# CTRL_MMR0 register map
Vendor: Texas Instruments
Peripheral module from a debugger description file (folder J7ES).
Registers are 32-bit, access per field, reset 0x0 unless marked. A register's access mark holds for its fields unless they carry their own. Offsets are as the file gives them; lines under a group give offsets from that group; [hi:lo] are bit positions; {n}, {i} and the like mark numbered series; 'fields as' and 'values as' point back to an identical list; <NAME> marks a mode.

## CTRL_MMR0 (part 1 of 2)
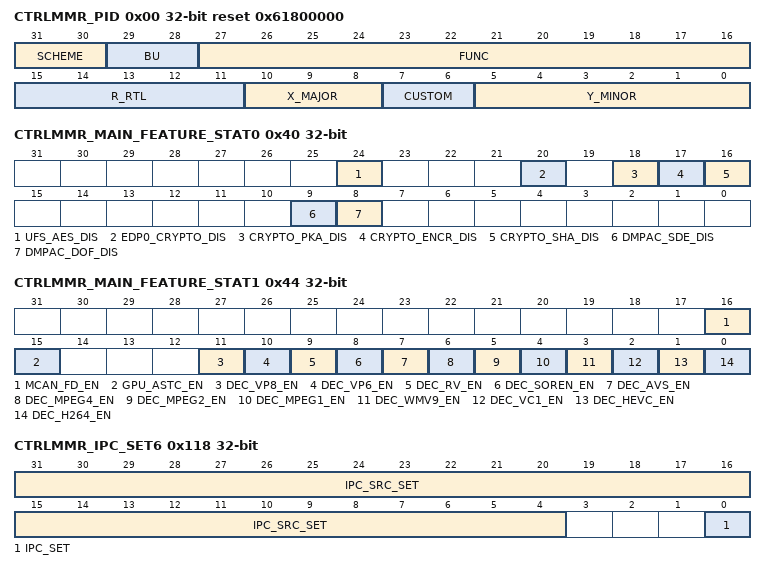
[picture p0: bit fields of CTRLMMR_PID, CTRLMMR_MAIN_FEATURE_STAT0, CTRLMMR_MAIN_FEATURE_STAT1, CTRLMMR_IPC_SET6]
0x00 CTRLMMR_PID ro reset 0x61800000 — Peripheral release details.
  [31:30] SCHEME
  [29:28] BU — Business unit
  [27:16] FUNC — Module functional identifier
  [15:11] R_RTL — RTL revision
  [10:8] X_MAJOR — Major revision
  [7:6] CUSTOM — Custom revision
  [5:0] Y_MINOR — Minor revision
0x08 CTRLMMR_MMR_CFG1 ro reset 0x8000009F — Indicates the MMR configuration.
  [7:0] PARTITIONS — Indicates present partitions
0x30 CTRLMMR_MAIN_DEVSTAT (reset mask 0xFFFFFF00) — Indicates SoC bootstrap selection. The default value of this register is determined by the SoC bootstrap pins when the por_boot_cfg_srst_n input is de-asserted. Note that this register will not be valid when returning from Deepsleep powerdown modes as the bootstrap pins are not relatched in this scenario.
  [7:0] BOOTMODE rw — Specifies the device Primary and Backup boot media.
0x34 CTRLMMR_MAIN_BOOTCFG ro (reset mask 0xFFFFFF00) — Indicates SoC bootstrap selection latched at power-on reset by PORz. The default value of this register is determined by the SoC bootstrap pins when the MMR por_boot_cfg_srst_n input is de-asserted and will remain until the SOC bootstrap pins are re-latched on a subsequent MMR por_boot_cfg_srst_n rising edge. Note that this register will not be valid when returning from Deepsleep powerdown modes as the bootstrap pins are not relatched in this scenario.
  [7:0] BOOTMODE — Specifies the device Primary and Backup boot media.
0x40 CTRLMMR_MAIN_FEATURE_STAT0 ro (reset mask 0xFEE8FCFC) — Indicates enable status of MAIN domain IP features.
  [24] UFS_AES_DIS — AES disabled on UFS
  [20] EDP0_CRYPTO_DIS — HDCP Cryptography disabled on eDP0
  [18] CRYPTO_PKA_DIS — SA2_UL Crypto Module PKA disabled
  [17] CRYPTO_ENCR_DIS — SA2_UL Crypto Module AES/3DES/DBRG disabled
  [16] CRYPTO_SHA_DIS — SA2_UL Crypto Module SHA/MD5 disabled
  [9] DMPAC_SDE_DIS — DMPAC Stereo Disparity Engine disabled
  [8] DMPAC_DOF_DIS — DMPAC Dense Optical Flow disabled
0x44 CTRLMMR_MAIN_FEATURE_STAT1 ro (reset mask 0xFFFE7000) — Indicates enable status of MAIN domain IP features.
  [16] MCAN_FD_EN — FD mode is supported on MAIN MCAN interfaces when set
  [15] GPU_ASTC_EN — GPU Adaptive Scalable Texture Compression is supported when set
  [11] DEC_VP8_EN — VP8 Video decode is enabled when set
  [10] DEC_VP6_EN — VP6 Video decode is enabled when set
  [9] DEC_RV_EN — RealVideo Video decode is enabled when set
  [8] DEC_SOREN_EN — Sorenson Video decode is enabled when set
  [7] DEC_AVS_EN — AVS Video decode is enabled when set
  [6] DEC_MPEG4_EN — MPEG4 Video decode is enabled when set
  [5] DEC_MPEG2_EN — MPEG2 Video decode is enabled when set
  [4] DEC_MPEG1_EN — MPEG1 Video decode is enabled when set
  [3] DEC_WMV9_EN — WMV9 Video decode is enabled when set
  [2] DEC_VC1_EN — VC-1 (SMPTE 421M) Video decode is enabled when set
  [1] DEC_HEVC_EN — HEVC (H.265) Video decode is enabled when set
  [0] DEC_H264_EN — H.264 Video decode is enabled when set
0x118 CTRLMMR_IPC_SET6 access not given — Generate interprocessor communication interrupt to C66 core0.
  [31:4] IPC_SRC_SET — Read returns current value (access W1TS)
  [0] IPC_SET — Read returns 0 (access W1TS)
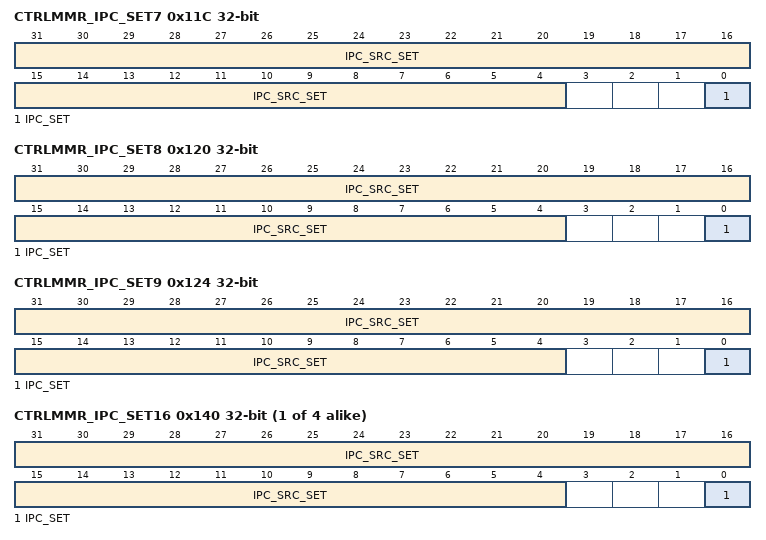
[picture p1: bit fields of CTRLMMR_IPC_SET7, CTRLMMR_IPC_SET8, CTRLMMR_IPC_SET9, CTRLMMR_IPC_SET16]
0x11C CTRLMMR_IPC_SET7 access not given — Generate interprocessor communication interrupt to C66 core1.
  fields as CTRLMMR_IPC_SET6
0x120 CTRLMMR_IPC_SET8 access not given — Generate interprocessor communication interrupt to ARM MPU core0.
  fields as CTRLMMR_IPC_SET6
0x124 CTRLMMR_IPC_SET9 access not given — Generate interprocessor communication interrupt to ARM MPU core1.
  fields as CTRLMMR_IPC_SET6
{0x100+4i} CTRLMMR_IPC_SET{i} access not given (i=16..19) — Generate interprocessor communication interrupt to MAIN R5 core{i-16}.
  fields as CTRLMMR_IPC_SET6
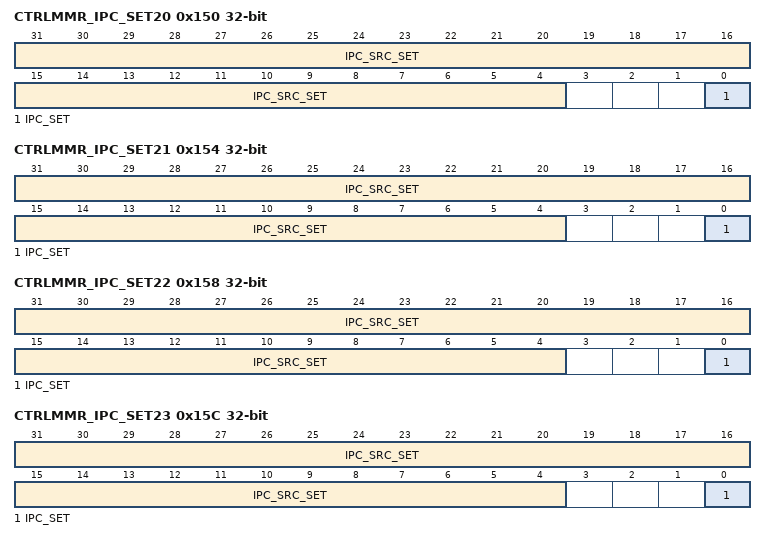
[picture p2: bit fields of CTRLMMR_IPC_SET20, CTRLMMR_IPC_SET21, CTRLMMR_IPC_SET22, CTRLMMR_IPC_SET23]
0x150 CTRLMMR_IPC_SET20 access not given — Generate interprocessor communication interrupt to ICSSG0 PRU0.
  fields as CTRLMMR_IPC_SET6
0x154 CTRLMMR_IPC_SET21 access not given — Generate interprocessor communication interrupt to ICSSG0 PRU1.
  fields as CTRLMMR_IPC_SET6
0x158 CTRLMMR_IPC_SET22 access not given — Generate interprocessor communication interrupt to ICSSG1 PRU0.
  fields as CTRLMMR_IPC_SET6
0x15C CTRLMMR_IPC_SET23 access not given — Generate interprocessor communication interrupt to ICSSG1 PRU1.
  fields as CTRLMMR_IPC_SET6
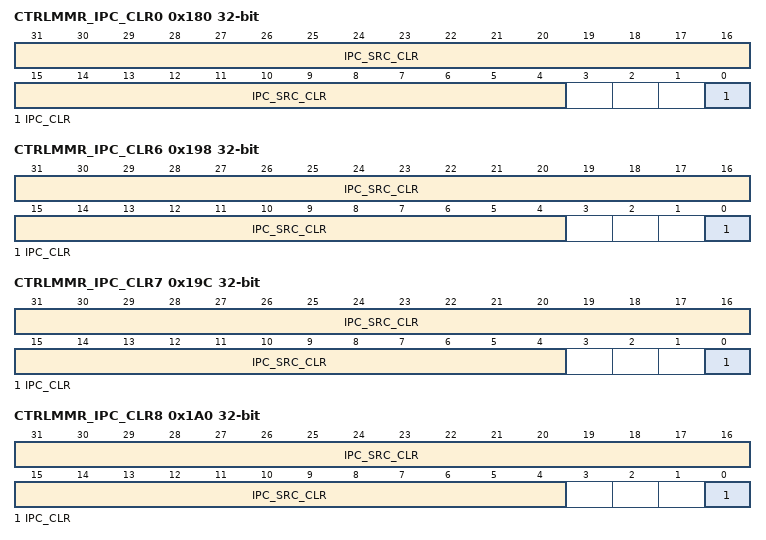
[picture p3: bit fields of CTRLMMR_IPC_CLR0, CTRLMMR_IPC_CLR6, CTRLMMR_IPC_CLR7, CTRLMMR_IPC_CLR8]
0x180 CTRLMMR_IPC_CLR0 access not given — Acknowledge interprocessor communication interrupt to C71x core0.
  [31:4] IPC_SRC_CLR — Read returns current value (access W1TC)
  [0] IPC_CLR — Read returns current value (access W1TC)
0x198 CTRLMMR_IPC_CLR6 access not given — Acknowledge interprocessor communication interrupt to C66 core0.
  fields as CTRLMMR_IPC_CLR0
0x19C CTRLMMR_IPC_CLR7 access not given — Acknowledge interprocessor communication interrupt to C66 core1.
  fields as CTRLMMR_IPC_CLR0
0x1A0 CTRLMMR_IPC_CLR8 access not given — Acknowledge interprocessor communication interrupt to ARM MPU core0.
  fields as CTRLMMR_IPC_CLR0
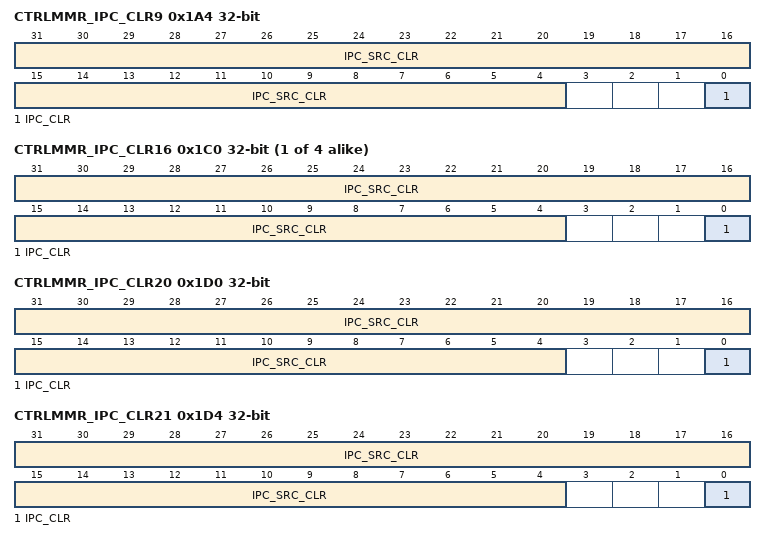
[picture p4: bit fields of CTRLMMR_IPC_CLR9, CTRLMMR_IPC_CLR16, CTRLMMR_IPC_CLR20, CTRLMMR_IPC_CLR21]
0x1A4 CTRLMMR_IPC_CLR9 access not given — Acknowledge interprocessor communication interrupt to ARM MPU core1.
  fields as CTRLMMR_IPC_CLR0
{0x180+4i} CTRLMMR_IPC_CLR{i} access not given (i=16..19) — Acknowledge interprocessor communication interrupt to MAIN R5 core{i-16}.
  fields as CTRLMMR_IPC_CLR0
0x1D0 CTRLMMR_IPC_CLR20 access not given — Acknowledge interprocessor communication interrupt to ICSSG0 PRU0.
  fields as CTRLMMR_IPC_CLR0
0x1D4 CTRLMMR_IPC_CLR21 access not given — Acknowledge interprocessor communication interrupt to ICSSG0 PRU1.
  fields as CTRLMMR_IPC_CLR0
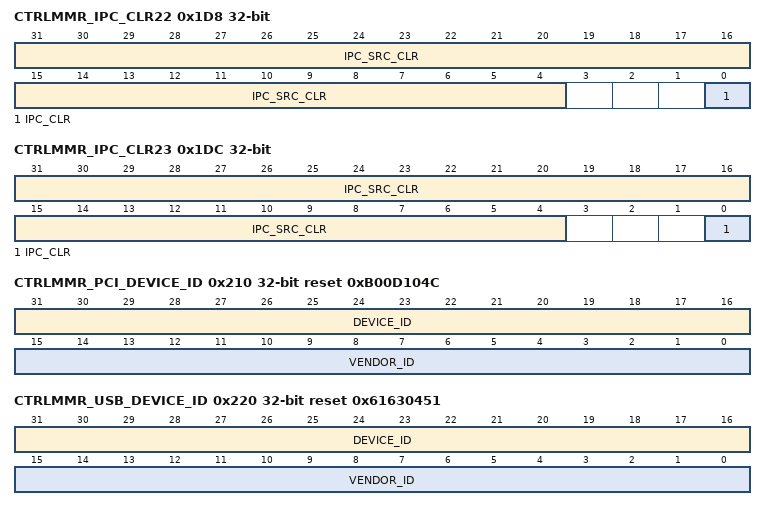
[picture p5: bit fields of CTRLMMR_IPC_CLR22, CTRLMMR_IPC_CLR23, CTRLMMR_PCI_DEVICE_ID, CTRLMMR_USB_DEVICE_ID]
0x1D8 CTRLMMR_IPC_CLR22 access not given — Acknowledge interprocessor communication interrupt to ICSSG1 PRU0.
  fields as CTRLMMR_IPC_CLR0
0x1DC CTRLMMR_IPC_CLR23 access not given — Acknowledge interprocessor communication interrupt to ICSSG1 PRU1.
  fields as CTRLMMR_IPC_CLR0
0x210 CTRLMMR_PCI_DEVICE_ID ro reset 0xB00D104C — PCIe device ID and vendor ID register.
  [31:16] DEVICE_ID — Product ID
  [15:0] VENDOR_ID — TI Vendor ID
0x220 CTRLMMR_USB_DEVICE_ID ro reset 0x61630451 — USB device and vendor ID register.
  [31:16] DEVICE_ID — Product ID
  [15:0] VENDOR_ID — TI Vendor ID
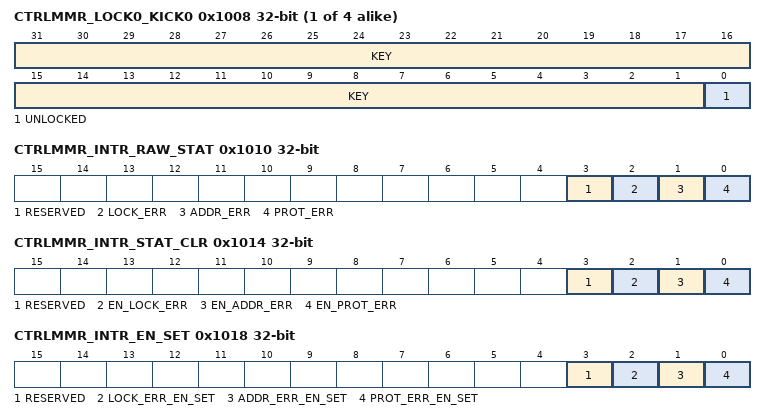
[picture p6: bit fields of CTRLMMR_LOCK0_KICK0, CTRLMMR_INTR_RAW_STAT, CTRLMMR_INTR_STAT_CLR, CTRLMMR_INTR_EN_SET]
{0x1008+0x4000*i} CTRLMMR_LOCK{i}_KICK0 (i=0..3) — Lower 32-bits of Partition{i} write lock key. This register must be written with the designated key value followed by a write to with its key value before write-protected Partition {i} registers can be written.
  [31:1] KEY rw — Write the kick0 unlock value followed by the kick1 unlock value to unlock the write-protected Partition{i} registers
  [0] UNLOCKED ro — Unlock status. When set indicates that the proper unlock sequence has been performed and the partition is unlocked for writing.
{0x100C+0x4000*i} CTRLMMR_LOCK{i}_KICK1 rw (i=0..3) — Upper 32-bits of Partition {i} write lock key. This register must be written with the designated key value after a write to with its key value before write-protected Partition {i} registers can be written.
  [31:0] KEY — Write the kick1 unlock value after the kick0 unlock value to unlock the write-protected Partition{i} registers
0x1010 CTRLMMR_INTR_RAW_STAT access not given — Shows the interrupt status (before enabling) and allows setting of the interrupt status (for test).
  [3] RESERVED — (access W1TS)
  [2] LOCK_ERR — Lock violation occurred (attempt to write a write-locked register with partition locked) (access W1TS)
  [1] ADDR_ERR — Address violation occurred (attempt to read or write an invalid register address) (access W1TS)
  [0] PROT_ERR — Protection violation occurred (attempt to read or write a register with insufficient security or privilege access rights) (access W1TS)
0x1014 CTRLMMR_INTR_STAT_CLR access not given — Shows the enabled interrupt status and allows the interrupt to be cleared.
  [3] RESERVED — (access W1TC)
  [2] EN_LOCK_ERR — Enabled lock interrupt event status (access W1TC)
  [1] EN_ADDR_ERR — Enabled address interrupt event status (access W1TC)
  [0] EN_PROT_ERR — Enabled protection interrupt event status (access W1TC)
0x1018 CTRLMMR_INTR_EN_SET access not given — Allows interrupt enables to be set.
  [3] RESERVED — (access W1TS)
  [2] LOCK_ERR_EN_SET — Lock interrupt enable (access W1TS)
  [1] ADDR_ERR_EN_SET — Address interrupt enable (access W1TS)
  [0] PROT_ERR_EN_SET — Protection interrupt enable (access W1TS)
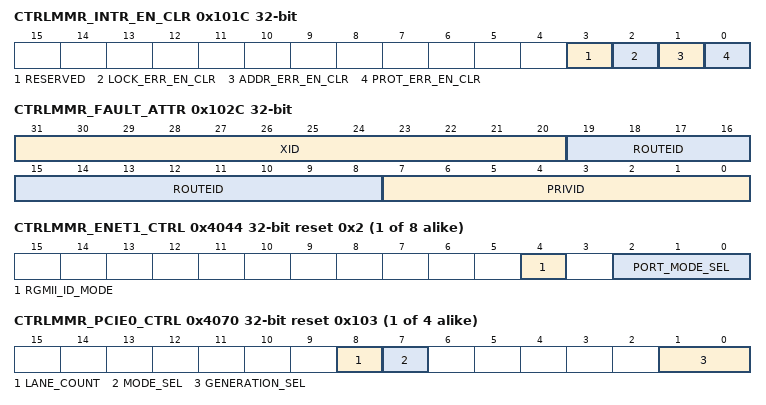
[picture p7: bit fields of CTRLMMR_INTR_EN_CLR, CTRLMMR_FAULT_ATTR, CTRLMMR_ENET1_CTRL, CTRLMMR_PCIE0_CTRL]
0x101C CTRLMMR_INTR_EN_CLR access not given — Allows interrupt enables to be cleared.
  [3] RESERVED — (access W1TC)
  [2] LOCK_ERR_EN_CLR — Lock interrupt disable (access W1TC)
  [1] ADDR_ERR_EN_CLR — Address interrupt disable (access W1TC)
  [0] PROT_ERR_EN_CLR — Protection interrupt disable (access W1TC)
0x1020 CTRLMMR_EOI — EOI Vector value. This register should be written with interrupt distribution value required by the device architecture to indicate service completion of the MMR interrupt. The EOI register is used to re-trigger the pulse interrupt signal to ensure that any nested interrupt events are serviced. The software interrupt handler must write to the EOI register at the end of the current interrupt processing routine, so that new events can re-trigger the pulse interrupt signal again. For level interrupt signals the EOI register is not functional and must not be used.
  [7:0] VECTOR rw
0x1024 CTRLMMR_FAULT_ADDR ro — Indicates the address of the first transfer that caused a fault to occur.
  [31:0] ADDRESS — Address of the faulted access
0x1028 CTRLMMR_FAULT_TYPE ro — Indicates the access type of the first transfer that caused a fault to occur.
  [5:0] TYPE — Type of access which faulted 0h - No fault 1h - User execute access 2h - User write access 4h - User read access 8h - Supervisor execute access 10h - Supervisor write access 20h - Supervisor read access
0x102C CTRLMMR_FAULT_ATTR ro — Indicates the attributes of the first transfer that caused a fault to occur.
  [31:20] XID — Transaction ID
  [19:8] ROUTEID
  [7:0] PRIVID — Privilege ID
0x1030 CTRLMMR_FAULT_CLR access not given — Allows software to clear the current fault Clearing the current fault allows the , , and registers to latch the attributes of the next fault that occurs. This does not affect the fault interrupt event itself. The interrupt must be cleared using the appropriate INTR_STATUS_CLR register bits.
  [0] CLEAR — Fault clear (access W1TC)
0x4000 CTRLMMR_USB0_CTRL — Controls USB0 operation.
  [27] SERDES_SEL rw — Serdes Selection.
0x4010 CTRLMMR_USB1_CTRL — Controls USB1 operation.
  [27] SERDES_SEL rw — Serdes Selection.
{0x4040+4i} CTRLMMR_ENET{i}_CTRL reset 0x2 (i=1..8) — Controls Ethernet Port{i} operation.
  [4] RGMII_ID_MODE rw — Port{i} RGMII internal transmit delay selection
  [2:0] PORT_MODE_SEL rw — Selects Ethernet switch Port{i} interface 0h - GMII/MII (not supported) 1h - RMII 2h - RGMII 3h - SGMII 4h - QSGMII 5h - XFI (not supported) 6h - QSGMII_SUB 7h - Reserved
{0x4070+4i} CTRLMMR_PCIE{i}_CTRL reset 0x103 (i=0..3) — Controls PCIe{i} operation.
  [8] LANE_COUNT rw — Configures the PCIe lane count
  [7] MODE_SEL rw — Selects the operating mode
  [1:0] GENERATION_SEL rw — Configures the PCIe generation support in the PCIe capabilities linked-list 0h - Reserved 1h - Gen2 - Controller advertises Gen1 &amp; Gen2 capability and link operates at either speed 2h - Gen3 - Controller advertises Gen1, Gen2, &amp; Gen3 capability and link operates at any of the three speeds 3h - Gen4 - Controller advertises Gen1, Gen2, Gen3, &amp; Gen4 capability and link operates at any of the four speeds
0x4080 CTRLMMR_SERDES0_LN0_CTRL — Controls 2-L SERDES0 lane0 selection.
  [1:0] LANE_FUNC_SEL rw — Selects the SERDES0 lane0 function 0h - Enet Switch Q/SGMII Lane 1 1h - PCIe0 Lane0 2h - For USB0 lane swap. Select this if USB0 was implemented with Type C connector 3h - Not used
0x4084 CTRLMMR_SERDES0_LN1_CTRL — Controls 2-L SERDES0 lane1 selection.
  [1:0] LANE_FUNC_SEL rw — Selects the SERDES0 lane1 function 0h - IP1 - Enet Switch Q/SGMII Lane 2 1h - IP2 - PCIe0 Lane1 2h - IP3 - USB0 3h - IP4 - Not Used
0x4090 CTRLMMR_SERDES1_LN0_CTRL — Controls 2-L SERDES1 lane0 selection.
  [1:0] LANE_FUNC_SEL rw — Selects the SERDES1 lane0 function 0h - Enet Switch Q/SGMII Lane 3 1h - PCIe1 Lane 0 2h - For USB1 lane swap. Select this if USB1 was implemented with Type C connector 3h - ICSS_G1 SGMII Lane 0
0x4094 CTRLMMR_SERDES1_LN1_CTRL — Controls 2-L SERDES1 lane1 selection.
  [1:0] LANE_FUNC_SEL rw — Selects the SERDES1 lane1 function 0h - Enet Switch Q/SGMII Lane 4 1h - PCIe1 Lane 1 2h - USB1 3h - ICSS_G1 SGMII Lane 1
0x40A0 CTRLMMR_SERDES2_LN0_CTRL — Controls 2-L SERDES2 lane0 selection.
  [1:0] LANE_FUNC_SEL rw — Selects the SERDES2 lane0 function 0h - Not Used 1h - PCIE2 Lane 0 2h - For USB1 lane swap. Select this if USB1 was implemented with Type C connector 3h - ICSS_G1 SGMII Lane 0
0x40A4 CTRLMMR_SERDES2_LN1_CTRL — Controls 2-L SERDES2 lane1 selection.
  [1:0] LANE_FUNC_SEL rw — Selects the SERDES2 lane1 function 0h - Not Used 1h - PCIE2 Lane 1 2h - USB1 3h - ICSS_G1 SGMII Lane 1
0x40B0 CTRLMMR_SERDES3_LN0_CTRL — Controls 2-L SERDES3 lane0 selection.
  [1:0] LANE_FUNC_SEL rw — Selects the SERDES3 lane0 function 0h - Not Used 1h - PCIE3 Lane 0 2h - For USB0 lane swap. Select this if USB0 was implemented with Type C connector 3h - Not Used
0x40B4 CTRLMMR_SERDES3_LN1_CTRL — Controls 2-L SERDES3 lane1 selection.
  [1:0] LANE_FUNC_SEL rw — Selects the SERDES3 lane1 function 0h - Not Used 1h - PCIE3 Lane 1 2h - USB0 3h - Not Used
{0x40C0+4i} CTRLMMR_SERDES4_LN{i}_CTRL (i=0..3) — Controls 4-L SERDES4 lane{i} selection.
  [1:0] LANE_FUNC_SEL rw — Selects the SERDES4 lane{i} function 0h - eDP Lane {i} 1h - Not Used 2h - Enet Switch Q/SGMII Lane {i+5} 3h - Not Used
{0x40E0+4i} CTRLMMR_SERDES{i}_CTRL (i=0..3) — Controls SERDES{i} operation.
  [8] RET_EN rw — Retention enable
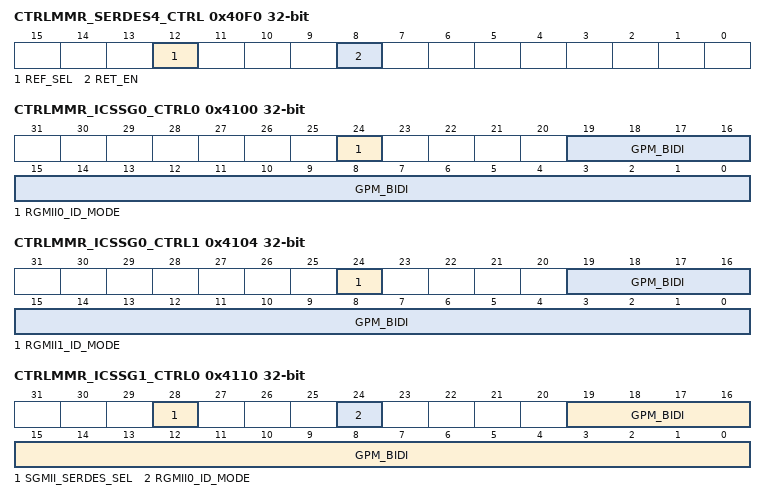
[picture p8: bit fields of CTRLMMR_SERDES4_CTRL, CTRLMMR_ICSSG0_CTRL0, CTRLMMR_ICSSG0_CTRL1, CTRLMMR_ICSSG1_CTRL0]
0x40F0 CTRLMMR_SERDES4_CTRL — Controls SERDES4 operation.
  [12] REF_SEL rw — REFCLK output select
  [8] RET_EN rw — Retention enable
0x4100 CTRLMMR_ICSSG0_CTRL0 — Controls ICSS_G0 operation.
  [24] RGMII0_ID_MODE rw — Controls the ICSS_G0 RGMII0 port internal transmit delay
  [19:0] GPM_BIDI rw — Controls operation of the ICSS_G0 PRU0_GPO pins. Each bit n controls the corresponding PRG0_PRU0GPOn I/O
0x4104 CTRLMMR_ICSSG0_CTRL1 — Controls ICSS_G0 operation.
  [24] RGMII1_ID_MODE rw — Controls the ICSS_G0 RGMII1 port internal transmit delay
  [19:0] GPM_BIDI rw — Controls operation of the ICSS_G0 PRU1_GPO pins. Each bit n controls the corresponding PRG0_PRU1GPOn I/O
0x4110 CTRLMMR_ICSSG1_CTRL0 — Controls ICSS_G1 operation.
  [28] SGMII_SERDES_SEL rw — SGMII0 Serdes Selection.
  [24] RGMII0_ID_MODE rw — Controls the ICSS_G1 RGMII0 port internal transmit delay
  [19:0] GPM_BIDI rw — Controls operation of the ICSS_G1 PRU0_GPO pins. Each bit n controls the corresponding PRG1_PRU0GPOn I/O
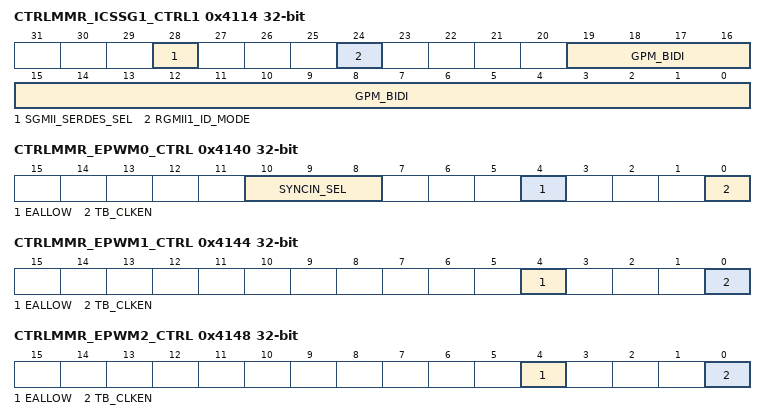
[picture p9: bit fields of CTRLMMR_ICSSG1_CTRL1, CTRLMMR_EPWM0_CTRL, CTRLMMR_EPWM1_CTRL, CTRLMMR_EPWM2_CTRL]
0x4114 CTRLMMR_ICSSG1_CTRL1 — Controls ICSS_G1 operation.
  [28] SGMII_SERDES_SEL rw — SGMII1 Serdes Selection.
  [24] RGMII1_ID_MODE rw — Controls the ICSS_G1 RGMII1 port internal transmit delay
  [19:0] GPM_BIDI rw — Controls operation of the ICSS_G1 PRU1_GPO pins. Each bit n controls the corresponding PRG1_PRU1GPOn I/O
0x4140 CTRLMMR_EPWM0_CTRL — Controls eHRPWM0 Operation.
  [10:8] SYNCIN_SEL rw — Selects the source of the PWM0 synchronization input 0h - PWM0_SYNCIN Pin 1h - None 2h - None 3h - None 4h - ICSSG0 Host Interrupt 6 5h - ICSSG1 Host Interrupt 6 6h - None 7h - None
  [4] EALLOW rw — Enable write access to ePWM tripzone and HRPWM config registers
  [0] TB_CLKEN rw — Enable eHRPWM timebase clock
0x4144 CTRLMMR_EPWM1_CTRL — Controls eHRPWM1 Operation.
  [4] EALLOW rw — Enable write access to ePWM tripzone and HRPWM config registers
  [0] TB_CLKEN rw — Enable eHRPWM timebase clock
0x4148 CTRLMMR_EPWM2_CTRL — Controls eHRPWM2 Operation.
  fields as CTRLMMR_EPWM1_CTRL
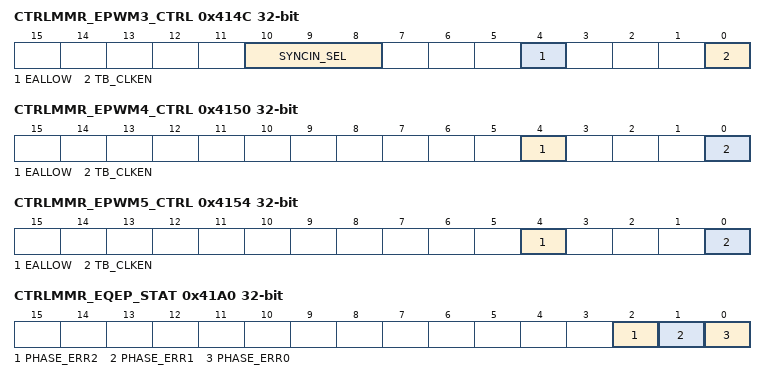
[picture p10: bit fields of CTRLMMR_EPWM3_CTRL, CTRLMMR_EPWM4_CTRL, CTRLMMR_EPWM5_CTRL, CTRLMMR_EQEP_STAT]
0x414C CTRLMMR_EPWM3_CTRL — Controls eHRPWM3 Operation.
  [10:8] SYNCIN_SEL rw — Selects the source of the PWM3 synchronization input 0h - PWM3_SYNCIN Pin 1h - PWM2 syncout signal, daisy chained 2h - None 3h - None 4h - ICSSG0 Host Interrupt 7 5h - ICSSG1 Host Interrupt 7 6h - None 7h - None
  [4] EALLOW rw — Enable write access to ePWM tripzone and HRPWM config registers
  [0] TB_CLKEN rw — Enable eHRPWM timebase clock
0x4150 CTRLMMR_EPWM4_CTRL — Controls eHRPWM4 Operation.
  fields as CTRLMMR_EPWM1_CTRL
0x4154 CTRLMMR_EPWM5_CTRL — Controls eHRPWM5 Operation.
  fields as CTRLMMR_EPWM1_CTRL
0x4160 CTRLMMR_SOCA_SEL — Selects Start of Conversion A output signal source. Each eHRPWM provides a SOCA event that can be used to trigger external ADCs. All eHRPWM SOCA events are ORed together allowing any of the 6 eHRPWMs to generate the event (if enabled within the eHRPWM). This event is then muxed with an ICSSx host interrupt allowing either an ICSSx or eHRPWMs to source the SOCA event pin.
  [1:0] SOCA_SEL rw — Selects the SOC A output source 0h - OR of all eHRPWM SOCA outputs 1h - ICSSG0 Host Interrupt 1 2h - ICSSG1 Host Interrupt 1 3h - None
0x4164 CTRLMMR_SOCB_SEL — Selects Start of Conversion B output signal source. Each eHRPWM provides a SOCB event that can be used to trigger external ADCs. All eHRPWM SOCB events are ORed together allowing any of the 6 eHRPWMs to generate the event (if enabled within the eHRPWM). This event is then muxed with an ICSSx host interrupt allowing either an ICSSx or eHRPWMs to source the SOCB event pin.
  [1:0] SOCB_SEL rw — Selects the SOC B output source 0h - OR of all eHRPWM SOCB ouputs 1h - ICSSG0 Host Interrupt 2 2h - ICSSG1 Host Interrupt 2 3h - None
0x41A0 CTRLMMR_EQEP_STAT ro (reset mask 0xFFFFFFF8) — Displays status of EQEP modules.
  [2] PHASE_ERR2 — eQEP2 Phase error status
  [1] PHASE_ERR1 — eQEP1 Phase error status
  [0] PHASE_ERR0 — eQEP0 Phase error status
0x41B4 CTRLMMR_SDIO1_CTRL (reset mask 0xFFFFFFE0) — Controls drive strength of MMC1 SDIO mode pins.
  [4:0] DRV_STR rw — Selects the SDIO drive strength
0x41B8 CTRLMMR_SDIO2_CTRL (reset mask 0xFFFFFFE0) — Controls drive strength of MMC2 SDIO mode pins.
  [4:0] DRV_STR rw — Selects the SDIO drive strength
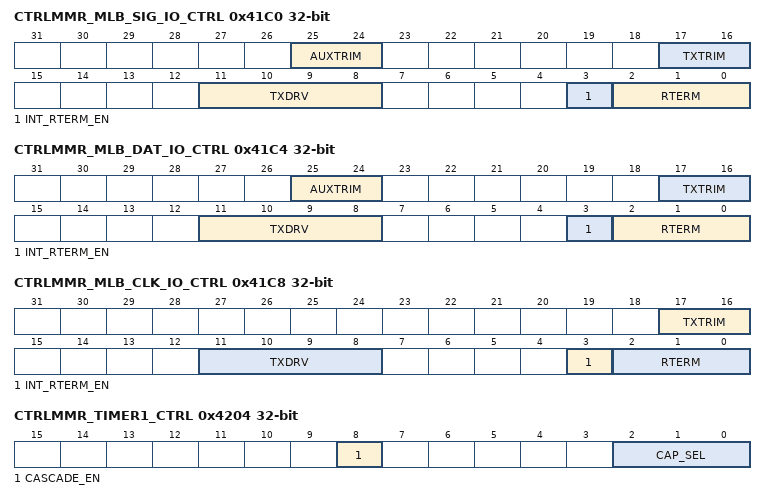
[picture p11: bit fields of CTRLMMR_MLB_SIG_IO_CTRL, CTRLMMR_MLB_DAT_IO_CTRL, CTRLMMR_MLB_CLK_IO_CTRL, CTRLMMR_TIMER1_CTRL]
0x41C0 CTRLMMR_MLB_SIG_IO_CTRL (reset mask 0xFCFCF0F0) — Controls the characteristics of the MLB SIG IO.
  [25:24] AUXTRIM rw — LVDS aux drive output current ratio trim for VOD offset compenstaion 0h - -8% 1h - 0% 2h - +9% 3h - +20%
  [17:16] TXTRIM rw — LVDS drive output current ratio trim 0h - -8% 1h - 0% 2h - +9% 3h - +20%
  [11:8] TXDRV rw — LVDS drive current. 0h - 0.0 mA 1h - 0.8 mA 2h - 1.6 mA 3h - 2.4 mA 4h - 3.2 mA 5h - 4.0 mA 6h - 4.8 mA 7h - 5.6 mA 8h - 6.4 mA 9h - 7.2 mA Ah - 8.0 mA Bh - 8.8 mA Ch - 9.6 mA Dh - 10.4 mA Eh - 11.2 mA Fh - 12.0 mA
  [3] INT_RTERM_EN rw — Internal termination resistor control
  [2:0] RTERM rw — Selects the internal termination resistor trim value. This bitfield is valid only if en_int_res is 1. Should be set to the correct value to provide 100 ohms. Typical termination values are: 0h - 77 ohm 1h - 81 ohm 2h - 86 ohm 3h - 91 ohm 4h - 96 ohm 5h - 102 ohm 6h - 110 ohm 7h - 118 ohm
0x41C4 CTRLMMR_MLB_DAT_IO_CTRL (reset mask 0xFCFCF0F0) — Controls the characteristics of the MLB DATA IO.
  [25:24] AUXTRIM rw — LVDS aux drive output current ratio trim for VOD offset compenstaion 0h - -8% 1h - 0% 2h - +9% 3h - +20%
  [17:16] TXTRIM rw — LVDS drive output current ratio trim 0h - -8% 1h - 0% 2h - +9% 3h - +20%
  [11:8] TXDRV rw — LVDS drive current. 0h - 0.0 mA 1h - 0.8 mA 2h - 1.6 mA 3h - 2.4 mA 4h - 3.2 mA 5h - 4.0 mA 6h - 4.8 mA 7h - 5.6 mA 8h - 6.4 mA 9h - 7.2 mA Ah - 8.0 mA Bh - 8.8 mA Ch - 9.6 mA Dh - 10.4 mA Eh - 11.2 mA Fh - 12.0 mA
  [3] INT_RTERM_EN rw — Internal termination resistor control:
  [2:0] RTERM rw — Selects the internal termination resistor trim value. This bitfield is valid only if en_int_res is 1. Should be set to the correct value to provide 100 ohms. Typical termination values are: 0h - 77 ohm 1h - 81 ohm 2h - 86 ohm 3h - 91 ohm 4h - 96 ohm 5h - 102 ohm 6h - 110 ohm 7h - 118 ohm
0x41C8 CTRLMMR_MLB_CLK_IO_CTRL (reset mask 0xFFFCF0F0) — Controls the characteristics of the MLB CLK IO.
  [17:16] TXTRIM rw — LVDS drive output current ratio trim 0h - -8% 1h - 0% 2h - +9% 3h - +20%
  [11:8] TXDRV rw — LVDS drive current. 0h - 0.0 mA 1h - 0.8 mA 2h - 1.6 mA 3h - 2.4 mA 4h - 3.2 mA 5h - 4.0 mA 6h - 4.8 mA 7h - 5.6 mA 8h - 6.4 mA 9h - 7.2 mA Ah - 8.0 mA Bh - 8.8 mA Ch - 9.6 mA Dh - 10.4 mA Eh - 11.2 mA Fh - 12.0 mA
  [3] INT_RTERM_EN rw — Internal termination resistor control:
  [2:0] RTERM rw — Selects the internal termination resistor trim value. This bitfield is valid only if en_int_res is 1. Should be set to the correct value to provide 100 ohms. Typical termination values are: 0h - 77 ohm 1h - 81 ohm 2h - 86 ohm 3h - 91 ohm 4h - 96 ohm 5h - 102 ohm 6h - 110 ohm 7h - 118 ohm
0x41D0 CTRLMMR_MLB_GPIO_CTRL reset 0x1 — Controls the MLB GPIO operation.
  [0] MLB_MODE_EN rw — Controls operation of MLB IOs
0x4200 CTRLMMR_TIMER0_CTRL — Controls TIMER0 operation.
  [2:0] CAP_SEL rw — Selects the TIMERIO input pin for capture input signal. This control is only used when TIMER0 is configured for capture operation. 0h - Use TIMERIO0 pin 1h - Use TIMERIO1 pin 2h - Use TIMERIO2 pin 3h - Use TIMERIO3 pin 4h - Use TIMERIO4 pin 5h - Use TIMERIO5 pin 6h - Use TIMERIO6 pin 7h - Use TIMERIO7 pin
0x4204 CTRLMMR_TIMER1_CTRL — Controls TIMER1 operation.
  [8] CASCADE_EN rw — Enables cascading of TIMER1 to TIMER0
  [2:0] CAP_SEL rw — Selects the TIMERIO input pin for capture input signal. This control is only used when TIMER1 is configured for capture operation. 0h - Use TIMERIO0 pin 1h - Use TIMERIO1 pin 2h - Use TIMERIO2 pin 3h - Use TIMERIO3 pin 4h - Use TIMERIO4 pin 5h - Use TIMERIO5 pin 6h - Use TIMERIO6 pin 7h - Use TIMERIO7 pin
0x4208 CTRLMMR_TIMER2_CTRL — Controls TIMER2 operation.
  [2:0] CAP_SEL rw — Selects the TIMERIO input pin for capture input signal. This control is only used when TIMER2 is configured for capture operation. 0h - Use TIMERIO0 pin 1h - Use TIMERIO1 pin 2h - Use TIMERIO2 pin 3h - Use TIMERIO3 pin 4h - Use TIMERIO4 pin 5h - Use TIMERIO5 pin 6h - Use TIMERIO6 pin 7h - Use TIMERIO7 pin
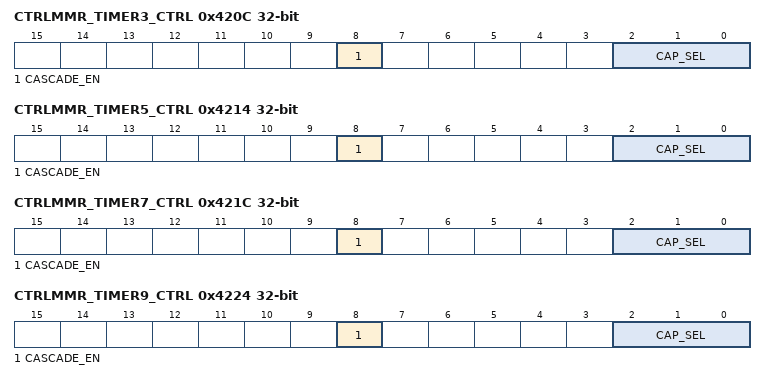
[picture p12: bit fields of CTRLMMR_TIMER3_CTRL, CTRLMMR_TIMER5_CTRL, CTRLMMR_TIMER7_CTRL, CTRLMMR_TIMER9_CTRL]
0x420C CTRLMMR_TIMER3_CTRL — Controls TIMER3 operation.
  [8] CASCADE_EN rw — Enables cascading of TIMER3 to TIMER2
  [2:0] CAP_SEL rw — Selects the TIMERIO input pin for capture input signal. This control is only used when TIMER3 is configured for capture operation. 0h - Use TIMERIO0 pin 1h - Use TIMERIO1 pin 2h - Use TIMERIO2 pin 3h - Use TIMERIO3 pin 4h - Use TIMERIO4 pin 5h - Use TIMERIO5 pin 6h - Use TIMERIO6 pin 7h - Use TIMERIO7 pin
0x4210 CTRLMMR_TIMER4_CTRL — Controls TIMER4 operation.
  [2:0] CAP_SEL rw — Selects the TIMERIO input pin for capture input signal. This control is only used when TIMER4 is configured for capture operation. 0h - Use TIMERIO0 pin 1h - Use TIMERIO1 pin 2h - Use TIMERIO2 pin 3h - Use TIMERIO3 pin 4h - Use TIMERIO4 pin 5h - Use TIMERIO5 pin 6h - Use TIMERIO6 pin 7h - Use TIMERIO7 pin
0x4214 CTRLMMR_TIMER5_CTRL — Controls TIMER5 operation.
  [8] CASCADE_EN rw — Enables cascading of TIMER5 to TIMER4
  [2:0] CAP_SEL rw — Selects the TIMERIO input pin for capture input signal. This control is only used when TIMER5 is configured for capture operation. 0h - Use TIMERIO0 pin 1h - Use TIMERIO1 pin 2h - Use TIMERIO2 pin 3h - Use TIMERIO3 pin 4h - Use TIMERIO4 pin 5h - Use TIMERIO5 pin 6h - Use TIMERIO6 pin 7h - Use TIMERIO7 pin
0x4218 CTRLMMR_TIMER6_CTRL — Controls TIMER6 operation.
  [2:0] CAP_SEL rw — Selects the TIMERIO input pin for capture input signal. This control is only used when TIMER6 is configured for capture operation. 0h - Use TIMERIO0 pin 1h - Use TIMERIO1 pin 2h - Use TIMERIO2 pin 3h - Use TIMERIO3 pin 4h - Use TIMERIO4 pin 5h - Use TIMERIO5 pin 6h - Use TIMERIO6 pin 7h - Use TIMERIO7 pin
0x421C CTRLMMR_TIMER7_CTRL — Controls TIMER7 operation.
  [8] CASCADE_EN rw — Enables cascading of TIMER7 to TIMER6
  [2:0] CAP_SEL rw — Selects the TIMERIO input pin for capture input signal. This control is only used when TIMER7 is configured for capture operation. 0h - Use TIMERIO0 pin 1h - Use TIMERIO1 pin 2h - Use TIMERIO2 pin 3h - Use TIMERIO3 pin 4h - Use TIMERIO4 pin 5h - Use TIMERIO5 pin 6h - Use TIMERIO6 pin 7h - Use TIMERIO7 pin
0x4220 CTRLMMR_TIMER8_CTRL — Controls TIMER8 operation.
  [2:0] CAP_SEL rw — Selects the TIMERIO input pin for capture input signal. This control is only used when TIMER8 is configured for capture operation. 0h - Use TIMERIO0 pin 1h - Use TIMERIO1 pin 2h - Use TIMERIO2 pin 3h - Use TIMERIO3 pin 4h - Use TIMERIO4 pin 5h - Use TIMERIO5 pin 6h - Use TIMERIO6 pin 7h - Use TIMERIO7 pin
0x4224 CTRLMMR_TIMER9_CTRL — Controls TIMER9 operation.
  [8] CASCADE_EN rw — Enables cascading of TIMER9 to TIMER8
  [2:0] CAP_SEL rw — Selects the TIMERIO input pin for capture input signal. This control is only used when TIMER9 is configured for capture operation. 0h - Use TIMERIO0 pin 1h - Use TIMERIO1 pin 2h - Use TIMERIO2 pin 3h - Use TIMERIO3 pin 4h - Use TIMERIO4 pin 5h - Use TIMERIO5 pin 6h - Use TIMERIO6 pin 7h - Use TIMERIO7 pin
0x4228 CTRLMMR_TIMER10_CTRL — Controls TIMER10 operation.
  [2:0] CAP_SEL rw — Selects the TIMERIO input pin for capture input signal. This control is only used when TIMER10 is configured for capture operation. 0h - Use TIMERIO0 pin 1h - Use TIMERIO1 pin 2h - Use TIMERIO2 pin 3h - Use TIMERIO3 pin 4h - Use TIMERIO4 pin 5h - Use TIMERIO5 pin 6h - Use TIMERIO6 pin 7h - Use TIMERIO7 pin
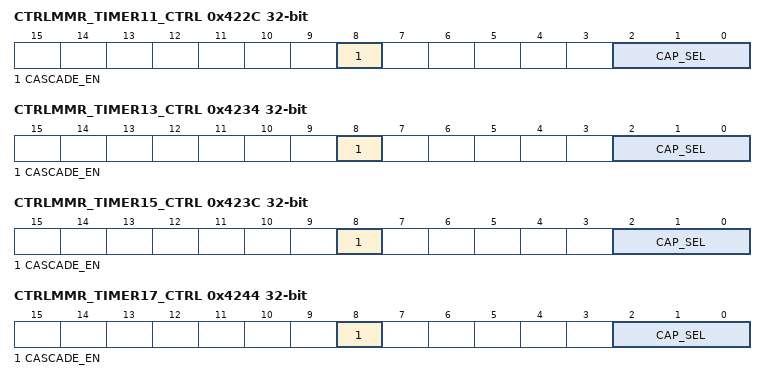
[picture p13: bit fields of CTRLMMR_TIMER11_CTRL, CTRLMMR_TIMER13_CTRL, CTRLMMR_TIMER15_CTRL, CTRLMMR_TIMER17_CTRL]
0x422C CTRLMMR_TIMER11_CTRL — Controls TIMER11 operation.
  [8] CASCADE_EN rw — Enables cascading of TIMER11 to TIMER10
  [2:0] CAP_SEL rw — Selects the TIMERIO input pin for capture input signal. This control is only used when TIMER11 is configured for capture operation. 0h - Use TIMERIO0 pin 1h - Use TIMERIO1 pin 2h - Use TIMERIO2 pin 3h - Use TIMERIO3 pin 4h - Use TIMERIO4 pin 5h - Use TIMERIO5 pin 6h - Use TIMERIO6 pin 7h - Use TIMERIO7 pin
0x4230 CTRLMMR_TIMER12_CTRL — Controls TIMER12 operation.
  [2:0] CAP_SEL rw — Selects the TIMERIO input pin for capture input signal. This control is only used when TIMER12 is configured for capture operation. 0h - Use TIMERIO0 pin 1h - Use TIMERIO1 pin 2h - Use TIMERIO2 pin 3h - Use TIMERIO3 pin 4h - Use TIMERIO4 pin 5h - Use TIMERIO5 pin 6h - Use TIMERIO6 pin 7h - Use TIMERIO7 pin
0x4234 CTRLMMR_TIMER13_CTRL — Controls TIMER13 operation.
  [8] CASCADE_EN rw — Enables cascading of TIMER13 to TIMER12
  [2:0] CAP_SEL rw — Selects the TIMERIO input pin for capture input signal. This control is only used when TIMER13 is configured for capture operation. 0h - Use TIMERIO0 pin 1h - Use TIMERIO1 pin 2h - Use TIMERIO2 pin 3h - Use TIMERIO3 pin 4h - Use TIMERIO4 pin 5h - Use TIMERIO5 pin 6h - Use TIMERIO6 pin 7h - Use TIMERIO7 pin
0x4238 CTRLMMR_TIMER14_CTRL — Controls TIMER14 operation.
  [2:0] CAP_SEL rw — Selects the TIMERIO input pin for capture input signal. This control is only used when TIMER14 is configured for capture operation. 0h - Use TIMERIO0 pin 1h - Use TIMERIO1 pin 2h - Use TIMERIO2 pin 3h - Use TIMERIO3 pin 4h - Use TIMERIO4 pin 5h - Use TIMERIO5 pin 6h - Use TIMERIO6 pin 7h - Use TIMERIO7 pin
0x423C CTRLMMR_TIMER15_CTRL — Controls TIMER15 operation.
  [8] CASCADE_EN rw — Enables cascading of TIMER15 to TIMER14
  [2:0] CAP_SEL rw — Selects the TIMERIO input pin for capture input signal. This control is only used when TIMER15 is configured for capture operation. 0h - Use TIMERIO0 pin 1h - Use TIMERIO1 pin 2h - Use TIMERIO2 pin 3h - Use TIMERIO3 pin 4h - Use TIMERIO4 pin 5h - Use TIMERIO5 pin 6h - Use TIMERIO6 pin 7h - Use TIMERIO7 pin
0x4240 CTRLMMR_TIMER16_CTRL — Controls TIMER16 operation.
  [2:0] CAP_SEL rw — Selects the TIMERIO input pin for capture input signal. This control is only used when TIMER16 is configured for capture operation. 0h - Use TIMERIO0 pin 1h - Use TIMERIO1 pin 2h - Use TIMERIO2 pin 3h - Use TIMERIO3 pin 4h - Use TIMERIO4 pin 5h - Use TIMERIO5 pin 6h - Use TIMERIO6 pin 7h - Use TIMERIO7 pin
0x4244 CTRLMMR_TIMER17_CTRL — Controls TIMER17 operation.
  [8] CASCADE_EN rw — Enables cascading of TIMER17 to TIMER16
  [2:0] CAP_SEL rw — Selects the TIMERIO input pin for capture input signal. This control is only used when TIMER17 is configured for capture operation. 0h - Use TIMERIO0 pin 1h - Use TIMERIO1 pin 2h - Use TIMERIO2 pin 3h - Use TIMERIO3 pin 4h - Use TIMERIO4 pin 5h - Use TIMERIO5 pin 6h - Use TIMERIO6 pin 7h - Use TIMERIO7 pin
0x4248 CTRLMMR_TIMER18_CTRL — Controls TIMER18 operation.
  [2:0] CAP_SEL rw — Selects the TIMERIO input pin for capture input signal. This control is only used when TIMER18 is configured for capture operation. 0h - Use TIMERIO0 pin 1h - Use TIMERIO1 pin 2h - Use TIMERIO2 pin 3h - Use TIMERIO3 pin 4h - Use TIMERIO4 pin 5h - Use TIMERIO5 pin 6h - Use TIMERIO6 pin 7h - Use TIMERIO7 pin
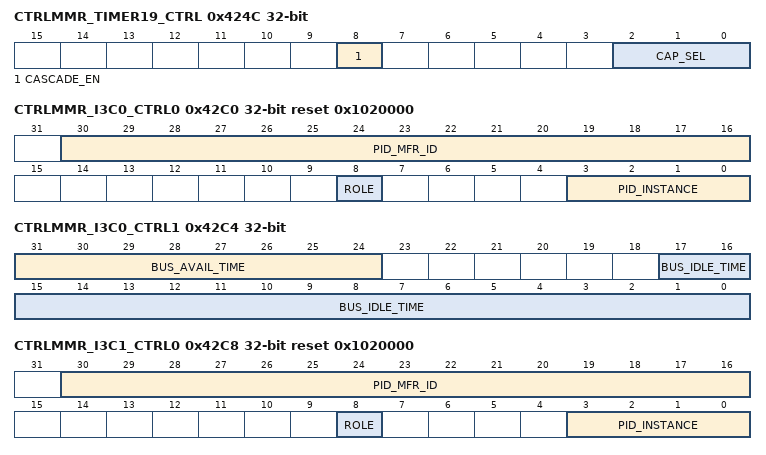
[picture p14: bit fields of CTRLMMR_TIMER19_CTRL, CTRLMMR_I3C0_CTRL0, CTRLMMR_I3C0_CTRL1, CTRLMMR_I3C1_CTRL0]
0x424C CTRLMMR_TIMER19_CTRL — Controls TIMER19 operation.
  [8] CASCADE_EN rw — Enables cascading of TIMER19 to TIMER18
  [2:0] CAP_SEL rw — Selects the TIMERIO input pin for capture input signal. This control is only used when TIMER19 is configured for capture operation. 0h - Use TIMERIO0 pin 1h - Use TIMERIO1 pin 2h - Use TIMERIO2 pin 3h - Use TIMERIO3 pin 4h - Use TIMERIO4 pin 5h - Use TIMERIO5 pin 6h - Use TIMERIO6 pin 7h - Use TIMERIO7 pin
{0x4280+4i} CTRLMMR_TIMERIO{i}_CTRL (i=0..7) — Controls TIMER_IO{i} muxing.
  [4:0] OUT_SEL rw — Selects the source of the TIMER_IO{i} output 0h - TIMERIO{i} is driven by TIMER0 output 1h - TIMERIO{i} is driven by TIMER1 output 2h - TIMERIO{i} is driven by TIMER2 output 3h - TIMERIO{i} is driven by TIMER3 output 4h - TIMERIO{i} is driven by TIMER4 output 5h - TIMERIO{i} is driven by TIMER5 output 6h - TIMERIO{i} is driven by TIMER6 output 7h - TIMERIO{i} is driven by TIMER7 output 8h - TIMERIO{i} is driven by TIMER8 output 9h - TIMERIO{i} is driven by TIMER9 output Ah - TIMERIO{i} is driven by TIMER10 output Bh - TIMERIO{i} is driven by TIMER11 output Ch - TIMERIO{i} is driven by TIMER12 output Dh - TIMERIO{i} is driven by TIMER13 output Eh - TIMERIO{i} is driven by TIMER14 output Fh - TIMERIO{i} is driven by TIMER15 output 10h - TIMERIO{i} is driven by TIMER16 output 11h - TIMERIO{i} is driven by TIMER17 output 12h - TIMERIO{i} is driven by TIMER18 output 13h - TIMERIO{i} is driven by TIMER19 output
0x42C0 CTRLMMR_I3C0_CTRL0 reset 0x1020000 — Controls I3C0 operation.
  [30:16] PID_MFR_ID rw — Manufacturer ID
  [8] ROLE rw — Master Role
  [3:0] PID_INSTANCE rw — Provisional ID Instance. This input corresponds to bits[15:12] of the Provisional ID. It is intended to provide a way of differentiating several I3C devices if there would be no other way to have each manufactured device have a unique Provisional ID
0x42C4 CTRLMMR_I3C0_CTRL1 — Controls I3C0 operation.
  [31:24] BUS_AVAIL_TIME rw — Indicates the number of sclk cycles in the Bus Available condition
  [17:0] BUS_IDLE_TIME rw — Indicates the number of sclk cycles in the Bus Idle condition
0x42C8 CTRLMMR_I3C1_CTRL0 reset 0x1020000 — Controls I3C1 operation.
  fields as CTRLMMR_I3C0_CTRL0
0x42CC CTRLMMR_I3C1_CTRL1 — Controls I3C1 operation.
  fields as CTRLMMR_I3C0_CTRL1
0x42E0 CTRLMMR_I2C0_CTRL — Controls I2C0 operation.
  [0] HS_MCS_EN rw — HS Mode master current source enable.
0x42E4 CTRLMMR_I2C1_CTRL — Controls I2C1 operation.
  [0] HS_MCS_EN rw — HS Mode master current source enable.
0x4300 CTRLMMR_DPHY_TX0_CTRL — Controls DPHY_TX0 Lane 0 operation.
  [1:0] LANE_FUNC_SEL rw — Selects the source for the 4 lanes of DPHY_TX 0 0h - IP1 (DSI0 PPI0) 1h - IP2 (CSI-TX0)
0x43F0 CTRLMMR_CSI_RX_LOOPBACK — Controls loopback of CSI-RX inputs to CSI-TX inputs for diagnostics.
  [3:0] CSITX_LB_SEL rw — Selects the CSI-RX loopback source for CSI-TX0 . These are shown as the CSI-TX0 connections below: 0h - CSI-RX0 3h - CSI-RX 1 6h - CSI-RX 2 9h - CSI-RX 3
0x4500 CTRLMMR_GPU_GP_IN_REQ — Generates GPIO input event to the GPU.
  [15] REQ rw — Input request. This bit is set to generate a GPIO request to the GPU to read the requestor data input. This bit should be cleared by the requestor after the GPU has acknowledged the request.
  [7:0] DATA rw — GPIO requestor data input to the GPU
0x4504 CTRLMMR_GPU_GP_IN_ACK ro (reset mask 0xFFFF7FFF) — Acknowledge for GPIO input event from the GPU.
  [15] ACK — Input acknowledge. The GPU will set this bit to acknowledge a GPIO input request. This will generate a gpu_gpio_ack interrupt which will be cleared when the requestor clears the req bit in the
0x4508 CTRLMMR_GPU_GP_OUT_REQ ro (reset mask 0xFFFF7F00) — Generates GPIO output event from the GPU.
  [15] REQ — Output request. This bit is set to generate a GPIO request from the GPU to read the requestor data output. This will generat a gpu_gpio_req interrupt which will be cleared when the receiver clears the ack bit in the GPU_GPIO_OUT_ACK register. This bit will be cleared by the GPU after the request has been acknowledged.
  [7:0] DATA — GPIO requestor data output from the GPU
0x450C CTRLMMR_GPU_GP_OUT_ACK — Acknowledge for GPIO output event to the GPU.
  [15] ACK rw — Output acknowledge. The receiver of the gpu_gpio_req interrupt will set this bit to acknowledge the GPIO output request. This bit is cleared when the GPU deasserts its gpio_output_req signal.
0x8000 CTRLMMR_OBSCLK0_CTRL reset 0x1F — This register controls which internal clock is made observable on the OBSCLK[2:0] output pins.
  [16] CLK_DIV_LD rw — Load the output divider value
  [15:8] CLK_DIV rw — OBSCLK0 output divider
  [4:0] CLK_SEL rw — OBSCLK0 clock source selection. 0h - MAIN_PLL0_HSDIV0_CLKOUT 1h - MAIN_PLL1_HSDIV0_CLKOUT 2h - MAIN_PLL2_HSDIV0_CLKOUT 3h - MAIN_PLL3_HSDIV0_CLKOUT 4h - MAIN_PLL4_HSDIV0_CLKOUT 5h - MAIN_PLL5_HSDIV0_CLKOUT 6h - MAIN_PLL6_HSDIV0_CLKOUT 7h - '0' 8h - '0' 9h - '0' Ah - '0' Bh - '0' Ch - MAIN_PLL12_HSDIV0_CLKOUT Dh - OBSCLK1 OUT Eh - MAIN_PLL14_HSDIV0_CLKOUT Fh - MAIN_PLL15_HSDIV0_CLKOUT 10h - MAIN_PLL16_HSDIV0_CLKOUT 11h - MAIN_PLL17_HSDIV0_CLKOUT 12h - MAIN_PLL18_HSDIV0_CLKOUT 13h - MAIN_PLL19_HSDIV0_CLKOUT 14h - UFS MPHY_TX_REF_SYMBOLCLK 15h - UFS MPHY_M31_VCO_19P2M_CLK 16h - UFS MPHY_M31_VCO_26M_CLK 17h - MAIN_PLL23_HSDIV0_CLKOUT 18h - MAIN_PLL24_HSDIV0_CLKOUT 19h - MAIN_PLL25_HSDIV0_CLKOUT 1Ah - CPTS_GENF3 1Bh - CLK_12M_RC 1Ch - WKUP_LFOSC0_CLKOUT 1Dh - PLLCTRL_OBSCLK 1Eh - HFOSC1_CLKOUT 1Fh - WKUP_HFOSC0_CLKOUT
0x8004 CTRLMMR_OBSCLK1_CTRL — This register controls which internal clock is made observable on the OBSCLK1_OUT internal clock signal.
  [1:0] CLK_SEL rw — OBSCLK1_OUT signal output clock source selection 0h - MAIN_PLL7_HSDIV0_CLKOUT / DIV4 1h - MAIN_PLL8_HSDIV0_CLKOUT / DIV8 2h - MAIN_PLL13_HSDIV0_CLKOUT / DIV4 3h - '0'
0x8010 CTRLMMR_CLKOUT_CTRL — Enables and selects clock source of CPSW CLKOUT pin.
  [4] CLK_EN rw — When set, enables CLKOUT output
  [0] CLK_SEL rw — Selects CLKOUT clock source
0x8030 CTRLMMR_GTC_CLKSEL — Selects the timebase clock source for the Global Timebase Counter.
  [3:0] CLK_SEL rw — Selects the GTC timebase clock source 0h - MAIN_PLL3_HSDIV1_CLKOUT 1h - MAIN_PLL0_HSDIV6_CLKOUT 2h - MCU_CPTS_REF_CLK (pin) 3h - CPTS_RFT_CLK (pin) 4h - MCU_EXT_REFCLK0 (pin) 5h - EXT_REFCLK1 (pin) 6h - SERDES0_IP2_LN0_TXMCLK 7h - SERDES0_IP2_LN1_TXMCLK 8h - SERDES1_IP2_LN0_TXMCLK 9h - SERDES1_IP2_LN1_TXMCLK Ah - SERDES2_IP2_LN0_TXMCLK Bh - SERDES2_IP2_LN1_TXMCLK Ch - SERDES3_IP2_LN0_TXMCLK Dh - SERDES3_IP2_LN1_TXMCLK Eh - MCU_PLL2_HSDIV1_CLKOUT Fh - MAIN_SYSCLK0
0x803C CTRLMMR_EFUSE_CLKSEL — Selects the functional clock source for the MAIN domain eFuse Controller.
  [0] CLK_SEL rw — Selects the clock source 0h - WKUP_HFOSC0_CLKOUT 1h - MAIN_SYSCLK0 / 4
0x8040 CTRLMMR_ICSSG0_CLKSEL — Selects the functional clock source for ICSS_G0.
  [19:16] IEP_CLKSEL rw — Selects the ICSSG0 IEP clock source 0h - MAIN_PLL3_HSDIV1_CLKOUT 1h - MAIN_PLL0_HSDIV6_CLKOUT 2h - MCU_CPTS_REF_CLK (pin) 3h - CPTS_RFT_CLK (pin) 4h - MCU_EXT_REFCLK0 (pin) 5h - EXT_REFCLK1 (pin) 6h - SERDES0_IP2_LN0_TXMCLK 7h - SERDES0_IP2_LN1_TXMCLK 8h - SERDES1_IP2_LN0_TXMCLK 9h - SERDES1_IP2_LN1_TXMCLK Ah - SERDES2_IP2_LN0_TXMCLK Bh - SERDES2_IP2_LN1_TXMCLK Ch - SERDES3_IP2_LN0_TXMCLK Dh - SERDES3_IP2_LN1_TXMCLK Eh - MCU_PLL2_HSDIV1_CLKOUT Fh - MAIN_SYSCLK0
  [0] CORE_CLKSEL rw — Selects the ICSSG0 functional clock source 0h - MAIN_PLL2_HSDIV0_CLKOUT 1h - MAIN_PLL3_HSDIV1_CLKOUT
0x8044 CTRLMMR_ICSSG1_CLKSEL — Selects the functional clock source for ICSS_G1.
  [19:16] IEP_CLKSEL rw — Selects the ICSSG1 IEP clock source 0h - MAIN_PLL3_HSDIV1_CLKOUT 1h - MAIN_PLL0_HSDIV6_CLKOUT 2h - MCU_CPTS_REF_CLK (pin) 3h - CPTS_RFT_CLK (pin) 4h - MCU_EXT_REFCLK0 (pin) 5h - EXT_REFCLK1 (pin) 6h - SERDES0_IP2_LN0_TXMCLK 7h - SERDES0_IP2_LN1_TXMCLK 8h - SERDES1_IP2_LN0_TXMCLK 9h - SERDES1_IP2_LN1_TXMCLK Ah - SERDES2_IP2_LN0_TXMCLK Bh - SERDES2_IP2_LN1_TXMCLK Ch - SERDES3_IP2_LN0_TXMCLK Dh - SERDES3_IP2_LN1_TXMCLK Eh - MCU_PLL2_HSDIV1_CLKOUT Fh - MAIN_SYSCLK0
  [0] CORE_CLKSEL rw — Selects the ICSSG1 functional clock source 0h - MAIN_PLL2_HSDIV0_CLKOUT 1h - MAIN_PLL3_HSDIV1_CLKOUT
